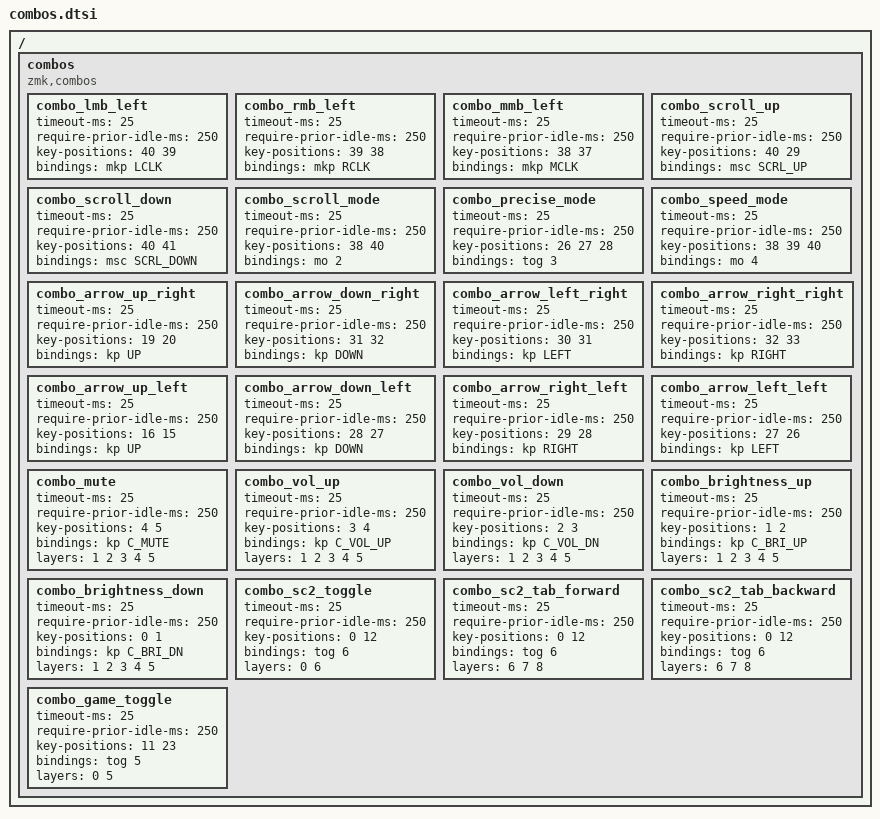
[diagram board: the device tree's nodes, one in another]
/ {
    combos {
        compatible = "zmk,combos";

        combo_lmb_left {
            timeout-ms = <25>;
            require-prior-idle-ms = <250>;
            key-positions = <40 39>;  // Left half M + ,
            bindings = <&mkp LCLK>;
        };

        combo_rmb_left {
            timeout-ms = <25>;
            require-prior-idle-ms = <250>;
            key-positions = <39 38>;  // Left half , + .
            bindings = <&mkp RCLK>;
        };

        combo_mmb_left {
            timeout-ms = <25>;
            require-prior-idle-ms = <250>;
            key-positions = <38 37>;  // Left half . + [
            bindings = <&mkp MCLK>;
        };

        combo_scroll_up {
            timeout-ms = <25>;
            require-prior-idle-ms = <250>;
            key-positions = <40 29>;  // H + .
            bindings = <&msc SCRL_UP>;
        };

        combo_scroll_down {
            timeout-ms = <25>;
            require-prior-idle-ms = <250>;
            key-positions = <40 41>;  // N + .
            bindings = <&msc SCRL_DOWN>;
        };

        combo_scroll_mode {
            timeout-ms = <25>;
            require-prior-idle-ms = <250>;
            key-positions = <38 40>;  // Left half M + .
            bindings = <&mo 2>;
        };

        combo_precise_mode {
            timeout-ms = <25>;
            require-prior-idle-ms = <250>;
            key-positions = <26 27 28>; 
            bindings = <&tog 3>;
        };

        combo_speed_mode {
            timeout-ms = <25>;
            require-prior-idle-ms = <250>;
            key-positions = <38 39 40>;
            bindings = <&mo 4>;
        };

        combo_arrow_up_right {
            timeout-ms = <25>;
            require-prior-idle-ms = <250>;
            key-positions = <19 20>;  // U + I
            bindings = <&kp UP>;
        };

        combo_arrow_down_right {
            timeout-ms = <25>;
            require-prior-idle-ms = <250>;
            key-positions = <31 32>;  // J + K
            bindings = <&kp DOWN>;
        };

        combo_arrow_left_right {
            timeout-ms = <25>;
            require-prior-idle-ms = <250>;
            key-positions = <30 31>;  // H + J
            bindings = <&kp LEFT>;
        };

        combo_arrow_right_right {
            timeout-ms = <25>;
            require-prior-idle-ms = <250>;
            key-positions = <32 33>;  // K + L
            bindings = <&kp RIGHT>;
        };

        combo_arrow_up_left {
            timeout-ms = <25>;
            require-prior-idle-ms = <250>;
            key-positions = <16 15>;  // Left half U + I
            bindings = <&kp UP>;
        };

        combo_arrow_down_left {
            timeout-ms = <25>;
            require-prior-idle-ms = <250>;
            key-positions = <28 27>;  // Left half J + K
            bindings = <&kp DOWN>;
        };

        combo_arrow_right_left {
            timeout-ms = <25>;
            require-prior-idle-ms = <250>;
            key-positions = <29 28>;  // Left half K + L
            bindings = <&kp RIGHT>;
        };

        combo_arrow_left_left {
            timeout-ms = <25>;
            require-prior-idle-ms = <250>;
            key-positions = <27 26>;  // Left half H + J
            bindings = <&kp LEFT>;
        };

        combo_mute {
            timeout-ms = <25>;
            require-prior-idle-ms = <250>;
            key-positions = <4 5>;    // 4 + 5
            bindings = <&kp C_MUTE>;
            layers = <1 2 3 4 5>;
        };

        combo_vol_up {
            timeout-ms = <25>;
            require-prior-idle-ms = <250>;
            key-positions = <3 4>;    // 3 + 4
            bindings = <&kp C_VOL_UP>;
            layers = <1 2 3 4 5>;
        };

        combo_vol_down {
            timeout-ms = <25>;
            require-prior-idle-ms = <250>;
            key-positions = <2 3>;    // 2 + 3
            bindings = <&kp C_VOL_DN>;
            layers = <1 2 3 4 5>;
        };

        combo_brightness_up {
            timeout-ms = <25>;
            require-prior-idle-ms = <250>;
            key-positions = <1 2>;    // 1 + 2
            bindings = <&kp C_BRI_UP>;
            layers = <1 2 3 4 5>;
        };

        combo_brightness_down {
            timeout-ms = <25>;
            require-prior-idle-ms = <250>;
            key-positions = <0 1>;    // NON_US_BACKSLASH + 1
            bindings = <&kp C_BRI_DN>;
            layers = <1 2 3 4 5>;
        };

        combo_sc2_toggle {
            timeout-ms = <25>;
            require-prior-idle-ms = <250>;
            key-positions = <0 12>;
            bindings = <&tog 6>;
            layers = <0 6>;
        };

        combo_sc2_tab_forward {
            timeout-ms = <25>;
            require-prior-idle-ms = <250>;
            key-positions = <0 12>;
            bindings = <&tog 6>;
            layers = <6 7 8>;
        };

        combo_sc2_tab_backward {
            timeout-ms = <25>;
            require-prior-idle-ms = <250>;
            key-positions = <0 12>;
            bindings = <&tog 6>;
            layers = <6 7 8>;
        };

        combo_game_toggle {
            timeout-ms = <25>;
            require-prior-idle-ms = <250>;
            key-positions = <11 23>;
            bindings = <&tog 5>;
            layers = <0 5>;
        };
    };
};
